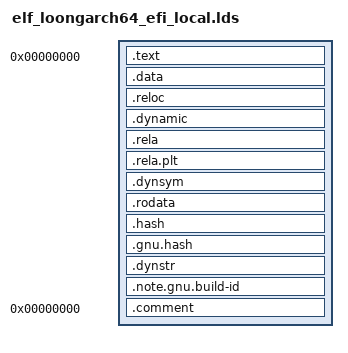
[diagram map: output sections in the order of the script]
/* SPDX-License-Identifier: GPL-2.0+ */
/*
 * Linker script for LoongArch64 EFI images that carry their own PE/COFF
 * header (crt0-efi-loongarch64-local.S), for use with "objcopy -O binary".
 * Section order and symbol names follow elf_riscv64_efi_local.lds:
 *   .text, .data, .reloc, then a "rodata" region holding the dynamic
 *   relocation data (.dynamic/.rela/.dynsym) followed by .rodata.
 * _ev* = end of contents (virtual size), _e* = end after padding
 * (raw size). Padding lives inside the sections so objcopy writes it.
 *
 * Note: Generated by Claude AI
 *
 */
OUTPUT_FORMAT("elf64-loongarch", "elf64-loongarch", "elf64-loongarch")
OUTPUT_ARCH(loongarch)
ENTRY(_start)
SECTIONS
{
  . = 0;
  ImageBase = .;
  .text : {
    *(.text.head)
    . = ALIGN(4096);
    _text = .;
    *(.text)
    *(.text.*)
    *(.gnu.linkonce.t.*)
    *(.plt)
    . = ALIGN(16);
    _evtext = .;
    . = ALIGN(4096);
  }
  _etext = .;
  _text_size = _etext - _text;
  _text_vsize = _evtext - _text;

  _data = .;
  .data :
  {
    *(.sdata)
    *(.data)
    *(.data1)
    *(.data.*)
    *(.got.plt)
    *(.got)

    . = ALIGN(16);
    __init_array_start = .;
    *(SORT(.init_array.*))
    *(.init_array)
    __init_array_end = .;
    . = ALIGN(16);
    __CTOR_LIST__ = .;
    *(SORT(.ctors.*))
    *(.ctors)
    __CTOR_END__ = .;
    . = ALIGN(16);
    __DTOR_LIST__ = .;
    *(SORT(.dtors.*))
    *(.dtors)
    __DTOR_END__ = .;
    . = ALIGN(16);
    __fini_array_start = .;
    *(SORT(.fini_array.*))
    *(.fini_array)
    __fini_array_end = .;

    /* the EFI loader doesn't like a .bss section: fold it into .data */
    . = ALIGN(16);
    _bss = .;
    *(.sbss)
    *(.scommon)
    *(.dynbss)
    *(.bss*)
    *(COMMON)
    *(.rel.local)
    . = ALIGN(16);
    _bss_end = .;
    _evdata = .;
    . = ALIGN(4096);
  }
  _edata = .;
  _data_size = _edata - _data;
  _data_vsize = _evdata - _data;

  _reloc = .;
  .reloc :
  {
    KEEP (*(.reloc))
    _evreloc = .;
    . = ALIGN(4096);
  }
  _ereloc = .;
  _reloc_size = _ereloc - _reloc;
  _reloc_vsize = _evreloc - _reloc;

  _rodata = .;
  _DYNAMIC = .;
  .dynamic : { *(.dynamic) }
  .rela :
  {
    *(.rela.text*)
    *(.rela.data*)
    *(.rela.got)
    *(.rela.dyn)
    *(.rela.stab)
    *(.rela.init_array*)
    *(.rela.fini_array*)
    *(.rela.ctors*)
    *(.rela.dtors*)
  }
  .rela.plt : { *(.rela.plt) }
  .dynsym : { *(.dynsym) }
  .rodata :
  {
    *(.rodata*)
    _evrodata = .;
    . = ALIGN(4096);
  }
  _erodata = .;
  _rodata_size = _erodata - _rodata;
  _rodata_vsize = _evrodata - _rodata;
  _image_end = .;
  _alldata_size = _image_end - _data;

  /* Not part of the PE image: after _image_end, not in objcopy -j list */
  .hash : { *(.hash) }
  .gnu.hash : { *(.gnu.hash) }
  .dynstr : { *(.dynstr) }
  .note.gnu.build-id : { *(.note.gnu.build-id) }

  /DISCARD/ :
  {
    *(.rela.reloc)
    *(.eh_frame)
    *(.eh_frame_hdr)
    *(.gcc_except_table*)
    *(.note.GNU-stack)
  }
  .comment 0 : { *(.comment) }
}
